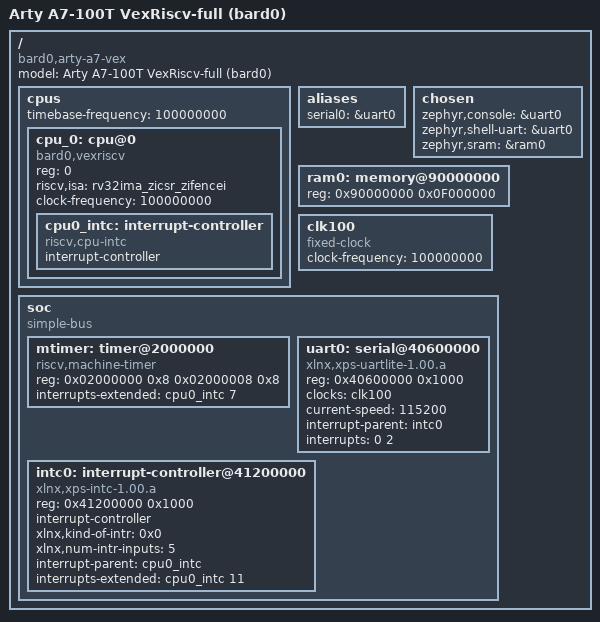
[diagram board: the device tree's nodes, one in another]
// SPDX-License-Identifier: Apache-2.0
// Copyright (c) 2026 Leonardo Capossio - bard0 design
//
// Zephyr DTS for the Arty A7-100T VexRiscv-full shell (hardware built by
// hardware/scripts/build_arty_a7_vex.py). Address map matches the MicroBlaze
// V shell where possible; the differences are the CPU node (VexRiscv, not
// AMD MicroBlaze V) and the timer (riscv,machine-timer instead of AMD
// xps-timer). Peripheral IRQs run through an axi_intc @ 0x41200000; its
// output drives VexRiscv's externalInterrupt bit, and Zephyr dispatches
// per-line via the xlnx,xps-intc-1.00.a driver (same as the MBV shell).

/dts-v1/;

/ {
	#address-cells = <1>;
	#size-cells = <1>;
	model = "Arty A7-100T VexRiscv-full (bard0)";
	compatible = "bard0,arty-a7-vex";

	cpus {
		#address-cells = <1>;
		#size-cells = <0>;
		timebase-frequency = <100000000>;

		cpu_0: cpu@0 {
			compatible = "bard0,vexriscv", "riscv";
			device_type = "cpu";
			reg = <0>;
			riscv,isa = "rv32ima_zicsr_zifencei";
			clock-frequency = <100000000>;

			cpu0_intc: interrupt-controller {
				compatible = "riscv,cpu-intc";
				interrupt-controller;
				#interrupt-cells = <1>;
			};
		};
	};

	aliases {
		serial0 = &uart0;
	};

	chosen {
		zephyr,console = &uart0;
		zephyr,shell-uart = &uart0;
		zephyr,sram = &ram0;
	};

	// DDR3 backing store, 240 MiB usable (0x9000_0000 .. 0x9EFF_FFFF, same
	// as the MBV shell so images bake the same load address). fcapz stages
	// the Zephyr image here; the boot ROM at 0x0 jumps in.
	ram0: memory@90000000 {
		device_type = "memory";
		reg = <0x90000000 0x0F000000>;
	};

	clk100: clk100 {
		compatible = "fixed-clock";
		#clock-cells = <0>;
		clock-frequency = <100000000>;
	};

	soc {
		#address-cells = <1>;
		#size-cells = <1>;
		compatible = "simple-bus";
		ranges;

		// riscv_mtimer.v — mtime.lo @ +0, mtime.hi @ +4,
		// mtimecmp.lo @ +8, mtimecmp.hi @ +12. Zephyr's binding takes
		// two ranges (mtime + mtimecmp) so name them separately.
		mtimer: timer@2000000 {
			compatible = "riscv,machine-timer";
			reg = <0x02000000 0x8 0x02000008 0x8>;
			reg-names = "mtime", "mtimecmp";
			interrupts-extended = <&cpu0_intc 7>;   // M-mode timer
		};

		// Xilinx AXI UARTLite @ 0x40600000. IRQ 0 on the axi_intc.
		uart0: serial@40600000 {
			compatible = "xlnx,xps-uartlite-1.00.a";
			reg = <0x40600000 0x1000>;
			clocks = <&clk100>;
			current-speed = <115200>;
			interrupt-parent = <&intc0>;
			interrupts = <0 2>;
			status = "okay";
		};

		// Xilinx AXI INTC @ 0x41200000. Same peripheral as the MBV
		// shell, dispatching to VexRiscv's externalInterrupt (M-mode
		// external IRQ = riscv,cpu-intc line 11). IRQ input map:
		//   In0 = uart0
		//   In1 = gpio0 (unused by Zephyr; wired for parity)
		//   In2 = axi_dma mm2s
		//   In3 = axi_dma s2mm
		//   In4 = emaczero
		intc0: interrupt-controller@41200000 {
			compatible = "xlnx,xps-intc-1.00.a";
			reg = <0x41200000 0x1000>;
			interrupt-controller;
			#interrupt-cells = <2>;
			xlnx,kind-of-intr = <0x0>;
			xlnx,num-intr-inputs = <5>;
			interrupt-parent = <&cpu0_intc>;
			interrupts-extended = <&cpu0_intc 11>;
		};
	};
};
